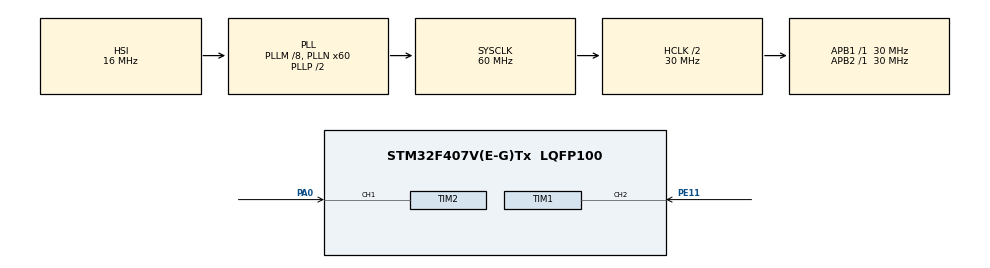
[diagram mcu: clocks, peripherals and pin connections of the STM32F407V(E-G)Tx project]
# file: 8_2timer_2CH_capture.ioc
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Dma.Request0=TIM1_CH2
Dma.Request1=TIM2_CH1
Dma.TIM1_CH2.0.Direction=DMA_PERIPH_TO_MEMORY
Dma.TIM1_CH2.0.FIFOMode=DMA_FIFOMODE_DISABLE
Dma.TIM1_CH2.0.Instance=DMA2_Stream2
Dma.TIM1_CH2.0.MemDataAlignment=DMA_MDATAALIGN_WORD
Dma.TIM1_CH2.0.MemInc=DMA_MINC_ENABLE
Dma.TIM1_CH2.0.Mode=DMA_CIRCULAR
Dma.TIM1_CH2.0.PeriphDataAlignment=DMA_PDATAALIGN_WORD
Dma.TIM1_CH2.0.PeriphInc=DMA_PINC_DISABLE
Dma.TIM1_CH2.0.Priority=DMA_PRIORITY_LOW
Dma.TIM2_CH1.1.Direction=DMA_PERIPH_TO_MEMORY
Dma.TIM2_CH1.1.FIFOMode=DMA_FIFOMODE_DISABLE
Dma.TIM2_CH1.1.Instance=DMA1_Stream5
Dma.TIM2_CH1.1.MemDataAlignment=DMA_MDATAALIGN_WORD
Dma.TIM2_CH1.1.MemInc=DMA_MINC_ENABLE
Dma.TIM2_CH1.1.Mode=DMA_CIRCULAR
Dma.TIM2_CH1.1.PeriphDataAlignment=DMA_PDATAALIGN_WORD
Dma.TIM2_CH1.1.PeriphInc=DMA_PINC_DISABLE
Dma.TIM2_CH1.1.Priority=DMA_PRIORITY_LOW
Mcu.Family=STM32F4
Mcu.Name=STM32F407V(E-G)Tx
Mcu.Package=LQFP100
NVIC.DMA1_Stream5_IRQn=true\:0\:0\:false\:false\:true\:false
NVIC.DMA2_Stream2_IRQn=true\:0\:0\:false\:false\:true\:false
NVIC.PriorityGroup=NVIC_PRIORITYGROUP_4
PA0-WKUP.Signal=S_TIM2_CH1_ETR
PA13.Mode=Serial_Wire
PA13.Signal=SYS_JTMS-SWDIO
PA14.Mode=Serial_Wire
PA14.Signal=SYS_JTCK-SWCLK
PE11.Signal=S_TIM1_CH2
ProjectManager.HeapSize=0x200
ProjectManager.StackSize=0x400
ProjectManager.TargetToolchain=MDK-ARM V5
RCC.48MHZClocksFreq_Value=30000000
RCC.AHBCLKDivider=RCC_SYSCLK_DIV2
RCC.AHBFreq_Value=30000000
RCC.APB1Freq_Value=30000000
RCC.APB1TimFreq_Value=30000000
RCC.APB2Freq_Value=30000000
RCC.APB2TimFreq_Value=30000000
RCC.CortexFreq_Value=30000000
RCC.HCLKFreq_Value=30000000
RCC.HSE_VALUE=25000000
RCC.HSI_VALUE=16000000
RCC.LSE_VALUE=32768
RCC.PLLM=8
RCC.PLLN=60
RCC.SYSCLKFreq_VALUE=60000000
RCC.SYSCLKSource=RCC_SYSCLKSOURCE_PLLCLK
RCC.VCOOutputFreq_Value=120000000
SH.S_TIM1_CH2.0=TIM1_CH2,Input_Capture2_from_TI2
SH.S_TIM2_CH1_ETR.0=TIM2_CH1,Input_Capture1_from_TI1
TIM1.Channel-Input_Capture2_from_TI2=TIM_CHANNEL_2
TIM1.ICFilter_CH2=15
TIM1.Period=65000
TIM1.Prescaler=29999
TIM2.Channel-Input_Capture1_from_TI1=TIM_CHANNEL_1
TIM2.ICFilter_CH1=15
TIM2.Period=100000
TIM2.Prescaler=29999
VP_TIM1_VS_ClockSourceINT.Mode=Internal
VP_TIM2_VS_ClockSourceINT.Mode=Internal
board=8_2timer_2CH_capture

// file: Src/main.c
/**
  ******************************************************************************
  * File Name          : main.c
  * Description        : Main program body
  ******************************************************************************
  ** This notice applies to any and all portions of this file
  * that are not between comment pairs USER CODE BEGIN and
  * USER CODE END. Other portions of this file, whether
  * inserted by the user or by software development tools
  * are owned by their respective copyright owners.
  *
  * COPYRIGHT(c) 2018 STMicroelectronics
  *
  * Redistribution and use in source and binary forms, with or without modification,
  * are permitted provided that the following conditions are met:
  *   1. Redistributions of source code must retain the above copyright notice,
  *      this list of conditions and the following disclaimer.
  *   2. Redistributions in binary form must reproduce the above copyright notice,
  *      this list of conditions and the following disclaimer in the documentation
  *      and/or other materials provided with the distribution.
  *   3. Neither the name of STMicroelectronics nor the names of its contributors
  *      may be used to endorse or promote products derived from this software
  *      without specific prior written permission.
  *
  * THIS SOFTWARE IS PROVIDED BY THE COPYRIGHT HOLDERS AND CONTRIBUTORS "AS IS"
  * AND ANY EXPRESS OR IMPLIED WARRANTIES, INCLUDING, BUT NOT LIMITED TO, THE
  * IMPLIED WARRANTIES OF MERCHANTABILITY AND FITNESS FOR A PARTICULAR PURPOSE ARE
  * DISCLAIMED. IN NO EVENT SHALL THE COPYRIGHT HOLDER OR CONTRIBUTORS BE LIABLE
  * FOR ANY DIRECT, INDIRECT, INCIDENTAL, SPECIAL, EXEMPLARY, OR CONSEQUENTIAL
  * DAMAGES (INCLUDING, BUT NOT LIMITED TO, PROCUREMENT OF SUBSTITUTE GOODS OR
  * SERVICES; LOSS OF USE, DATA, OR PROFITS; OR BUSINESS INTERRUPTION) HOWEVER
  * CAUSED AND ON ANY THEORY OF LIABILITY, WHETHER IN CONTRACT, STRICT LIABILITY,
  * OR TORT (INCLUDING NEGLIGENCE OR OTHERWISE) ARISING IN ANY WAY OUT OF THE USE
  * OF THIS SOFTWARE, EVEN IF ADVISED OF THE POSSIBILITY OF SUCH DAMAGE.
  *
  ******************************************************************************
  */
#include "main.h"
#include "stm32f4xx_hal.h"

/* USER CODE BEGIN Includes */
  uint32_t counter1=0,counter2=0;
  uint32_t val1_dma[1],val2_dma[1];
/* USER CODE END Includes */

TIM_HandleTypeDef htim1;
TIM_HandleTypeDef htim2;
DMA_HandleTypeDef hdma_tim1_ch2;
DMA_HandleTypeDef hdma_tim2_ch1;

/* USER CODE BEGIN PV */
/* Private variables ---------------------------------------------------------*/

/* USER CODE END PV */

void SystemClock_Config(void);
static void MX_GPIO_Init(void);
static void MX_DMA_Init(void);
static void MX_TIM2_Init(void);
static void MX_TIM1_Init(void);

/* USER CODE BEGIN PFP */
/* Private function prototypes -----------------------------------------------*/
void HAL_TIM_IC_CaptureCallback(TIM_HandleTypeDef *htim)
{ // her capturede islemler buna dallanir.

	if(htim->Instance==TIM1)
	{
		__HAL_TIM_SetCounter(&htim1,0);
		//capture tim1 den  olunca tim1 nin counterini 0 liyoruz.
	}

  if(htim->Instance==TIM2)
	{
		__HAL_TIM_SetCounter(&htim2,0);
		//capture tim2 den  olunca tim2 nin counterini 0 liyoruz.

	}
 // Kisacasi Capture meydana geldigi an o kalani  sifirliyoruz.

}
/* USER CODE END PFP */

int main(void)
{

  /* MCU Configuration----------------------------------------------------------*/

  /* Reset of all peripherals, Initializes the Flash interface and the Systick. */
  HAL_Init();

  /* Configure the system clock */
  SystemClock_Config();

  /* Initialize all configured peripherals */
  MX_GPIO_Init();
  MX_DMA_Init();
  MX_TIM2_Init();
  MX_TIM1_Init();

  /* USER CODE BEGIN 2 */
   HAL_TIM_IC_Start_DMA(&htim1,TIM_CHANNEL_2,(uint32_t*)val1_dma,1);
	 HAL_TIM_IC_Start_DMA(&htim2,TIM_CHANNEL_1,(uint32_t*)val2_dma,1);
// capture modda star ettigimiz için farkli IC ILE OLUYOR.
// IC input capture demektir.

/* USER CODE END 2 */

  /* Infinite loop */
  while (1)
  {
  counter1= __HAL_TIM_GetCounter(&htim1); // counter degerlerini aldik.
		 counter2= __HAL_TIM_GetCounter(&htim2);
		// bunlarin yaninda  ...hal_tim.c  dosyasinda interrupt dosyasinda capture fonksiyonuna git.
  }

}

/** System Clock Configuration
*/
void SystemClock_Config(void)
{

  RCC_OscInitTypeDef RCC_OscInitStruct;
  RCC_ClkInitTypeDef RCC_ClkInitStruct;

    /**Configure the main internal regulator output voltage
    */
  __HAL_RCC_PWR_CLK_ENABLE();

  __HAL_PWR_VOLTAGESCALING_CONFIG(PWR_REGULATOR_VOLTAGE_SCALE1);

    /**Initializes the CPU, AHB and APB busses clocks
    */
  RCC_OscInitStruct.OscillatorType = RCC_OSCILLATORTYPE_HSI;
  RCC_OscInitStruct.HSIState = RCC_HSI_ON;
  RCC_OscInitStruct.HSICalibrationValue = 16;
  RCC_OscInitStruct.PLL.PLLState = RCC_PLL_ON;
  RCC_OscInitStruct.PLL.PLLSource = RCC_PLLSOURCE_HSI;
  RCC_OscInitStruct.PLL.PLLM = 8;
  RCC_OscInitStruct.PLL.PLLN = 60;
  RCC_OscInitStruct.PLL.PLLP = RCC_PLLP_DIV2;
  RCC_OscInitStruct.PLL.PLLQ = 4;
  if (HAL_RCC_OscConfig(&RCC_OscInitStruct) != HAL_OK)
  {
    _Error_Handler(__FILE__, __LINE__);
  }

    /**Initializes the CPU, AHB and APB busses clocks
    */
  RCC_ClkInitStruct.ClockType = RCC_CLOCKTYPE_HCLK|RCC_CLOCKTYPE_SYSCLK
                              |RCC_CLOCKTYPE_PCLK1|RCC_CLOCKTYPE_PCLK2;
  RCC_ClkInitStruct.SYSCLKSource = RCC_SYSCLKSOURCE_PLLCLK;
  RCC_ClkInitStruct.AHBCLKDivider = RCC_SYSCLK_DIV2;
  RCC_ClkInitStruct.APB1CLKDivider = RCC_HCLK_DIV1;
  RCC_ClkInitStruct.APB2CLKDivider = RCC_HCLK_DIV1;

  if (HAL_RCC_ClockConfig(&RCC_ClkInitStruct, FLASH_LATENCY_0) != HAL_OK)
  {
    _Error_Handler(__FILE__, __LINE__);
  }

    /**Configure the Systick interrupt time
    */
  HAL_SYSTICK_Config(HAL_RCC_GetHCLKFreq()/1000);

    /**Configure the Systick
    */
  HAL_SYSTICK_CLKSourceConfig(SYSTICK_CLKSOURCE_HCLK);

  /* SysTick_IRQn interrupt configuration */
  HAL_NVIC_SetPriority(SysTick_IRQn, 0, 0);
}

/* TIM1 init function */
static void MX_TIM1_Init(void)
{

  TIM_ClockConfigTypeDef sClockSourceConfig;
  TIM_MasterConfigTypeDef sMasterConfig;
  TIM_IC_InitTypeDef sConfigIC;

  htim1.Instance = TIM1;
  htim1.Init.Prescaler = 29999;
  htim1.Init.CounterMode = TIM_COUNTERMODE_UP;
  htim1.Init.Period = 65000;
  htim1.Init.ClockDivision = TIM_CLOCKDIVISION_DIV1;
  htim1.Init.RepetitionCounter = 0;
  if (HAL_TIM_Base_Init(&htim1) != HAL_OK)
  {
    _Error_Handler(__FILE__, __LINE__);
  }

  sClockSourceConfig.ClockSource = TIM_CLOCKSOURCE_INTERNAL;
  if (HAL_TIM_ConfigClockSource(&htim1, &sClockSourceConfig) != HAL_OK)
  {
    _Error_Handler(__FILE__, __LINE__);
  }

  if (HAL_TIM_IC_Init(&htim1) != HAL_OK)
  {
    _Error_Handler(__FILE__, __LINE__);
  }

  sMasterConfig.MasterOutputTrigger = TIM_TRGO_RESET;
  sMasterConfig.MasterSlaveMode = TIM_MASTERSLAVEMODE_DISABLE;
  if (HAL_TIMEx_MasterConfigSynchronization(&htim1, &sMasterConfig) != HAL_OK)
  {
    _Error_Handler(__FILE__, __LINE__);
  }

  sConfigIC.ICPolarity = TIM_INPUTCHANNELPOLARITY_RISING;
  sConfigIC.ICSelection = TIM_ICSELECTION_DIRECTTI;
  sConfigIC.ICPrescaler = TIM_ICPSC_DIV1;
  sConfigIC.ICFilter = 15;
  if (HAL_TIM_IC_ConfigChannel(&htim1, &sConfigIC, TIM_CHANNEL_2) != HAL_OK)
  {
    _Error_Handler(__FILE__, __LINE__);
  }

}

/* TIM2 init function */
static void MX_TIM2_Init(void)
{

  TIM_ClockConfigTypeDef sClockSourceConfig;
  TIM_MasterConfigTypeDef sMasterConfig;
  TIM_IC_InitTypeDef sConfigIC;

  htim2.Instance = TIM2;
  htim2.Init.Prescaler = 29999;
  htim2.Init.CounterMode = TIM_COUNTERMODE_UP;
  htim2.Init.Period = 100000;
  htim2.Init.ClockDivision = TIM_CLOCKDIVISION_DIV1;
  if (HAL_TIM_Base_Init(&htim2) != HAL_OK)
  {
    _Error_Handler(__FILE__, __LINE__);
  }

  sClockSourceConfig.ClockSource = TIM_CLOCKSOURCE_INTERNAL;
  if (HAL_TIM_ConfigClockSource(&htim2, &sClockSourceConfig) != HAL_OK)
  {
    _Error_Handler(__FILE__, __LINE__);
  }

  if (HAL_TIM_IC_Init(&htim2) != HAL_OK)
  {
    _Error_Handler(__FILE__, __LINE__);
  }

  sMasterConfig.MasterOutputTrigger = TIM_TRGO_RESET;
  sMasterConfig.MasterSlaveMode = TIM_MASTERSLAVEMODE_DISABLE;
  if (HAL_TIMEx_MasterConfigSynchronization(&htim2, &sMasterConfig) != HAL_OK)
  {
    _Error_Handler(__FILE__, __LINE__);
  }

  sConfigIC.ICPolarity = TIM_INPUTCHANNELPOLARITY_RISING;
  sConfigIC.ICSelection = TIM_ICSELECTION_DIRECTTI;
  sConfigIC.ICPrescaler = TIM_ICPSC_DIV1;
  sConfigIC.ICFilter = 15;
  if (HAL_TIM_IC_ConfigChannel(&htim2, &sConfigIC, TIM_CHANNEL_1) != HAL_OK)
  {
    _Error_Handler(__FILE__, __LINE__);
  }

}

static void MX_DMA_Init(void)
{
  /* DMA controller clock enable */
  __HAL_RCC_DMA2_CLK_ENABLE();
  __HAL_RCC_DMA1_CLK_ENABLE();

  /* DMA interrupt init */
  /* DMA1_Stream5_IRQn interrupt configuration */
  HAL_NVIC_SetPriority(DMA1_Stream5_IRQn, 0, 0);
  HAL_NVIC_EnableIRQ(DMA1_Stream5_IRQn);
  /* DMA2_Stream2_IRQn interrupt configuration */
  HAL_NVIC_SetPriority(DMA2_Stream2_IRQn, 0, 0);
  HAL_NVIC_EnableIRQ(DMA2_Stream2_IRQn);

}

/** Configure pins as
        * Analog
        * Input
        * Output
        * EVENT_OUT
        * EXTI
*/
static void MX_GPIO_Init(void)
{

  /* GPIO Ports Clock Enable */
  __HAL_RCC_GPIOA_CLK_ENABLE();
  __HAL_RCC_GPIOE_CLK_ENABLE();

}

void _Error_Handler(char * file, int line)
{
  while(1)
  {
  }
}

/************************ (C) COPYRIGHT STMicroelectronics *****END OF FILE****/
